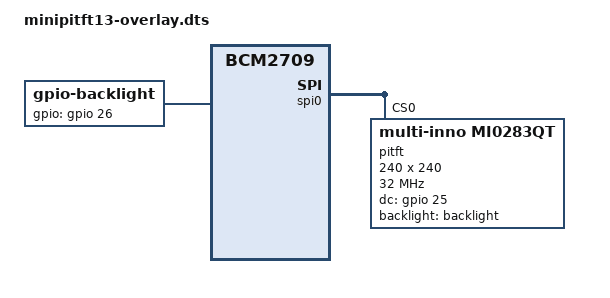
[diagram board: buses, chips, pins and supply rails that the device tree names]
/*
 * Device Tree overlay for Adafruit Mini PiTFT 1.3" and 1.5" 240x240 Display
 *
 */

/dts-v1/;
/plugin/;

/ {
	compatible = "brcm,bcm2835", "brcm,bcm2708", "brcm,bcm2709";

	fragment@0 {
		target = <&spi0>;
		__overlay__ {
			status = "okay";

			spidev@0{
				status = "disabled";
			};

		};
	};

	fragment@1 {
		target = <&gpio>;
		__overlay__ {
			pitft_pins: pitft_pins {
				brcm,pins = <25 26>; /* dc pin */
				brcm,function = <1 1>; /* out */
				brcm,pull = <0 1>; /* no pull */
			};
		};
	};

	fragment@2 {
		target = <&spi0>;
		__overlay__ {
			/* needed to avoid dtc warning */
			#address-cells = <1>;
			#size-cells = <0>;

			pitft: pitft@0{
				compatible = "multi-inno,mi0283qt";
				reg = <0>;
				pinctrl-names = "default";
				pinctrl-0 = <&pitft_pins>;

				spi-max-frequency = <32000000>;
				rotation = <0>;
				width = <240>;
				height = <240>;
				col_offset = <0>;
				row_offset = <0>;
				dc-gpios = <&gpio 25 0>;
				backlight = <&backlight>;
			};
		};
	};

	fragment@3 {
		target-path = "/soc";
		__overlay__ {
			backlight: backlight {
				compatible = "gpio-backlight";
				gpios = <&gpio 26 0>;
                default-on;
			};
		};
	};

	__overrides__ {
		speed =       <&pitft>,"spi-max-frequency:0";
		rotation =    <&pitft>,"rotation:0";
		width =       <&pitft>,"width:0";
		height =      <&pitft>,"height:0";
		col_offset =  <&pitft>,"col_offset:0";
		row_offset =  <&pitft>,"row_offset:0";
	};
};
